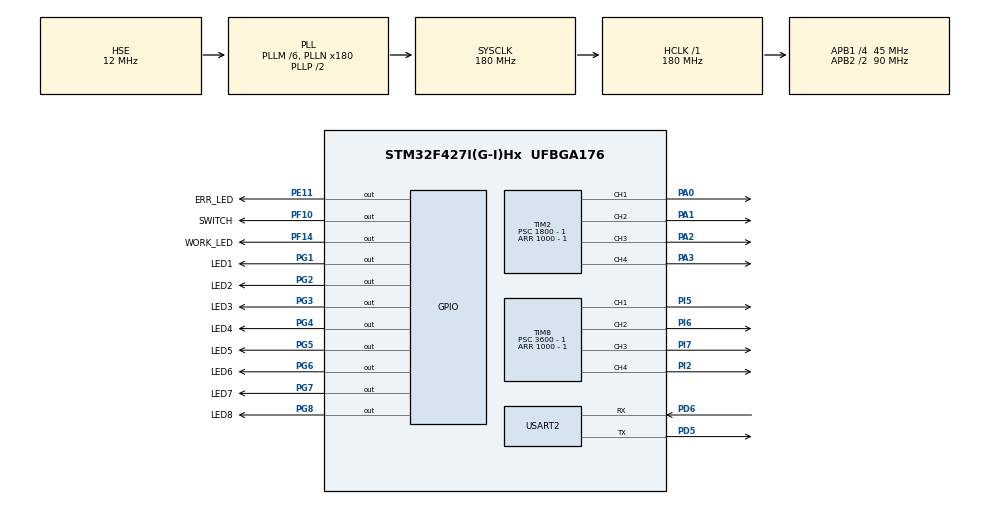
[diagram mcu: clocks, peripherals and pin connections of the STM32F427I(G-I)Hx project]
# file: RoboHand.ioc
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FREERTOS.Tasks01=root_task,24,640,root_task_handler,As weak,NULL,Dynamic,NULL,NULL
FREERTOS.configCHECK_FOR_STACK_OVERFLOW=2
FREERTOS.configENABLE_FPU=1
FREERTOS.configMINIMAL_STACK_SIZE=256
FREERTOS.configRECORD_STACK_HIGH_ADDRESS=1
FREERTOS.configTOTAL_HEAP_SIZE=51200
Mcu.Family=STM32F4
Mcu.Name=STM32F427I(G-I)Hx
Mcu.Package=UFBGA176
NVIC.PriorityGroup=NVIC_PRIORITYGROUP_4
NVIC.TIM1_BRK_TIM9_IRQn=true\:15\:0\:false\:false\:true\:false\:false\:true\:true
NVIC.TIM4_IRQn=true\:5\:0\:false\:false\:true\:true\:true\:true\:true
NVIC.TimeBase=TIM1_BRK_TIM9_IRQn
NVIC.TimeBaseIP=TIM9
NVIC.USART2_IRQn=true\:5\:0\:false\:false\:true\:true\:true\:true\:true
PA0/WKUP.Signal=S_TIM2_CH1_ETR
PA1.Signal=S_TIM2_CH2
PA13.Mode=Serial_Wire
PA13.Signal=SYS_JTMS-SWDIO
PA14.Mode=Serial_Wire
PA14.Signal=SYS_JTCK-SWCLK
PA2.Signal=S_TIM2_CH3
PA3.Signal=S_TIM2_CH4
PD5.Mode=Asynchronous
PD5.Signal=USART2_TX
PD6.Mode=Asynchronous
PD6.Signal=USART2_RX
PE11.GPIO_Label=ERR_LED
PE11.PinState=GPIO_PIN_SET
PE11.Signal=GPIO_Output
PF10.GPIO_Label=SWITCH
PF10.GPIO_ModeDefaultOutputPP=GPIO_MODE_OUTPUT_PP
PF10.GPIO_PuPd=GPIO_PULLDOWN
PF10.PinState=GPIO_PIN_RESET
PF10.Signal=GPIO_Output
PF14.GPIO_Label=WORK_LED
PF14.PinState=GPIO_PIN_SET
PF14.Signal=GPIO_Output
PG1.GPIO_Label=LED1
PG1.PinState=GPIO_PIN_SET
PG1.Signal=GPIO_Output
PG2.GPIO_Label=LED2
PG2.PinState=GPIO_PIN_SET
PG2.Signal=GPIO_Output
PG3.GPIO_Label=LED3
PG3.PinState=GPIO_PIN_SET
PG3.Signal=GPIO_Output
PG4.GPIO_Label=LED4
PG4.PinState=GPIO_PIN_SET
PG4.Signal=GPIO_Output
PG5.GPIO_Label=LED5
PG5.PinState=GPIO_PIN_SET
PG5.Signal=GPIO_Output
PG6.GPIO_Label=LED6
PG6.PinState=GPIO_PIN_SET
PG6.Signal=GPIO_Output
PG7.GPIO_Label=LED7
PG7.PinState=GPIO_PIN_SET
PG7.Signal=GPIO_Output
PG8.GPIO_Label=LED8
PG8.PinState=GPIO_PIN_SET
PG8.Signal=GPIO_Output
PH0/OSC_IN.Mode=HSE-External-Oscillator
PH0/OSC_IN.Signal=RCC_OSC_IN
PH1/OSC_OUT.Mode=HSE-External-Oscillator
PH1/OSC_OUT.Signal=RCC_OSC_OUT
PI2.Signal=S_TIM8_CH4
PI5.Signal=S_TIM8_CH1
PI6.Signal=S_TIM8_CH2
PI7.Signal=S_TIM8_CH3
ProjectManager.HeapSize=0x200
ProjectManager.StackSize=0x400
ProjectManager.TargetToolchain=CMake
RCC.48MHZClocksFreq_Value=90000000
RCC.AHBFreq_Value=180000000
RCC.APB1CLKDivider=RCC_HCLK_DIV4
RCC.APB1Freq_Value=45000000
RCC.APB1TimFreq_Value=90000000
RCC.APB2CLKDivider=RCC_HCLK_DIV2
RCC.APB2Freq_Value=90000000
RCC.APB2TimFreq_Value=180000000
RCC.CortexFreq_Value=180000000
RCC.HCLKFreq_Value=180000000
RCC.HSE_VALUE=12000000
RCC.HSI_VALUE=16000000
RCC.LSE_VALUE=32768
RCC.PLLM=6
RCC.PLLN=180
RCC.PLLSourceVirtual=RCC_PLLSOURCE_HSE
RCC.SYSCLKFreq_VALUE=180000000
RCC.SYSCLKSource=RCC_SYSCLKSOURCE_PLLCLK
RCC.VCOOutputFreq_Value=360000000
SH.S_TIM2_CH1_ETR.0=TIM2_CH1,PWM Generation1 CH1
SH.S_TIM2_CH2.0=TIM2_CH2,PWM Generation2 CH2
SH.S_TIM2_CH3.0=TIM2_CH3,PWM Generation3 CH3
SH.S_TIM2_CH4.0=TIM2_CH4,PWM Generation4 CH4
SH.S_TIM8_CH1.0=TIM8_CH1,PWM Generation1 CH1
SH.S_TIM8_CH2.0=TIM8_CH2,PWM Generation2 CH2
SH.S_TIM8_CH3.0=TIM8_CH3,PWM Generation3 CH3
SH.S_TIM8_CH4.0=TIM8_CH4,PWM Generation4 CH4
TIM2.AutoReloadPreload=TIM_AUTORELOAD_PRELOAD_ENABLE
TIM2.Channel-PWM\ Generation1\ CH1=TIM_CHANNEL_1
TIM2.Channel-PWM\ Generation2\ CH2=TIM_CHANNEL_2
TIM2.Channel-PWM\ Generation3\ CH3=TIM_CHANNEL_3
TIM2.Channel-PWM\ Generation4\ CH4=TIM_CHANNEL_4
TIM2.Period=1000 - 1
TIM2.Prescaler=1800 - 1
TIM4.AutoReloadPreload=TIM_AUTORELOAD_PRELOAD_ENABLE
TIM4.Period=1000 - 1
TIM4.Prescaler=90 - 1
TIM8.AutoReloadPreload=TIM_AUTORELOAD_PRELOAD_ENABLE
TIM8.Channel-PWM\ Generation1\ CH1=TIM_CHANNEL_1
TIM8.Channel-PWM\ Generation2\ CH2=TIM_CHANNEL_2
TIM8.Channel-PWM\ Generation3\ CH3=TIM_CHANNEL_3
TIM8.Channel-PWM\ Generation4\ CH4=TIM_CHANNEL_4
TIM8.Period=1000 - 1
TIM8.Prescaler=3600 - 1
USART2.VirtualMode=VM_ASYNC
VP_FREERTOS_VS_CMSIS_V2.Mode=CMSIS_V2
VP_SYS_VS_tim9.Mode=TIM9
VP_TIM2_VS_ClockSourceINT.Mode=Internal
VP_TIM4_VS_ClockSourceINT.Mode=Internal
VP_TIM8_VS_ClockSourceINT.Mode=Internal
board=custom

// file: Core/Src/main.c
/* USER CODE BEGIN Header */
/**
 ******************************************************************************
 * @file           : main.c
 * @brief          : Main program body
 ******************************************************************************
 * @attention
 *
 * Copyright (c) 2024 STMicroelectronics.
 * All rights reserved.
 *
 * This software is licensed under terms that can be found in the LICENSE file
 * in the root directory of this software component.
 * If no LICENSE file comes with this software, it is provided AS-IS.
 *
 ******************************************************************************
 */
/* USER CODE END Header */
#include "main.h"
#include "cmsis_os.h"
#include "tim.h"
#include "usart.h"
#include "gpio.h"

void SystemClock_Config(void);
void MX_FREERTOS_Init(void);

int main(void)
{

  /* MCU Configuration--------------------------------------------------------*/

  /* Reset of all peripherals, Initializes the Flash interface and the Systick. */
  HAL_Init();

  /* Configure the system clock */
  SystemClock_Config();

  /* Initialize all configured peripherals */
  MX_GPIO_Init();
  MX_TIM2_Init();
  MX_TIM8_Init();
  MX_USART2_UART_Init();
  MX_TIM4_Init();

  /* Init scheduler */
  osKernelInitialize();

  /* Call init function for freertos objects (in cmsis_os2.c) */
  MX_FREERTOS_Init();

  /* Start scheduler */
  osKernelStart();

  /* We should never get here as control is now taken by the scheduler */

  /* Infinite loop */
    while (1)
    {

    }
}

void SystemClock_Config(void)
{
  RCC_OscInitTypeDef RCC_OscInitStruct = {0};
  RCC_ClkInitTypeDef RCC_ClkInitStruct = {0};

  /** Configure the main internal regulator output voltage
  */
  __HAL_RCC_PWR_CLK_ENABLE();
  __HAL_PWR_VOLTAGESCALING_CONFIG(PWR_REGULATOR_VOLTAGE_SCALE1);

  /** Initializes the RCC Oscillators according to the specified parameters
  * in the RCC_OscInitTypeDef structure.
  */
  RCC_OscInitStruct.OscillatorType = RCC_OSCILLATORTYPE_HSE;
  RCC_OscInitStruct.HSEState = RCC_HSE_ON;
  RCC_OscInitStruct.PLL.PLLState = RCC_PLL_ON;
  RCC_OscInitStruct.PLL.PLLSource = RCC_PLLSOURCE_HSE;
  RCC_OscInitStruct.PLL.PLLM = 6;
  RCC_OscInitStruct.PLL.PLLN = 180;
  RCC_OscInitStruct.PLL.PLLP = RCC_PLLP_DIV2;
  RCC_OscInitStruct.PLL.PLLQ = 4;
  if (HAL_RCC_OscConfig(&RCC_OscInitStruct) != HAL_OK)
  {
    Error_Handler();
  }

  /** Activate the Over-Drive mode
  */
  if (HAL_PWREx_EnableOverDrive() != HAL_OK)
  {
    Error_Handler();
  }

  /** Initializes the CPU, AHB and APB buses clocks
  */
  RCC_ClkInitStruct.ClockType = RCC_CLOCKTYPE_HCLK|RCC_CLOCKTYPE_SYSCLK
                              |RCC_CLOCKTYPE_PCLK1|RCC_CLOCKTYPE_PCLK2;
  RCC_ClkInitStruct.SYSCLKSource = RCC_SYSCLKSOURCE_PLLCLK;
  RCC_ClkInitStruct.AHBCLKDivider = RCC_SYSCLK_DIV1;
  RCC_ClkInitStruct.APB1CLKDivider = RCC_HCLK_DIV4;
  RCC_ClkInitStruct.APB2CLKDivider = RCC_HCLK_DIV2;

  if (HAL_RCC_ClockConfig(&RCC_ClkInitStruct, FLASH_LATENCY_5) != HAL_OK)
  {
    Error_Handler();
  }
}

/* USER CODE BEGIN 4 */

__weak void Robo_App_Timer_Update(void)
{
}

/* USER CODE END 4 */

void HAL_TIM_PeriodElapsedCallback(TIM_HandleTypeDef *htim)
{
  if (htim->Instance == TIM9) {
    HAL_IncTick();
  }
  /* USER CODE BEGIN Callback 1 */
    if (htim == &htim4)
    {
        Robo_App_Timer_Update();
    }

  /* USER CODE END Callback 1 */
}

void Error_Handler(void)
{
    __disable_irq();
    while (1)
    {
    }
}

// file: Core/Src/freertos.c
/* USER CODE BEGIN Header */
/**
 ******************************************************************************
 * File Name          : freertos.c
 * Description        : Code for freertos applications
 ******************************************************************************
 * @attention
 *
 * Copyright (c) 2024 STMicroelectronics.
 * All rights reserved.
 *
 * This software is licensed under terms that can be found in the LICENSE file
 * in the root directory of this software component.
 * If no LICENSE file comes with this software, it is provided AS-IS.
 *
 ******************************************************************************
 */
/* USER CODE END Header */

#include "FreeRTOS.h"
#include "task.h"
#include "main.h"
#include "cmsis_os.h"

/* Definitions for root_task */
osThreadId_t root_taskHandle;
const osThreadAttr_t root_task_attributes = {
  .name = "root_task",
  .stack_size = 640 * 4,
  .priority = (osPriority_t) osPriorityNormal,
};

void root_task_handler(void *argument);

void MX_FREERTOS_Init(void); /* (MISRA C 2004 rule 8.1) */

/* Hook prototypes */
void vApplicationStackOverflowHook(xTaskHandle xTask, signed char *pcTaskName);

/* USER CODE BEGIN 4 */
void vApplicationStackOverflowHook(xTaskHandle xTask, signed char *pcTaskName)
{
    /* Run time stack overflow checking is performed if
    configCHECK_FOR_STACK_OVERFLOW is defined to 1 or 2. This hook function is
    called if a stack overflow is detected. */
}
/* USER CODE END 4 */

void MX_FREERTOS_Init(void) {

  /* Create the thread(s) */
  /* creation of root_task */
  root_taskHandle = osThreadNew(root_task_handler, NULL, &root_task_attributes);

}

__weak void root_task_handler(void *argument)
{
    for (;;)
    {
        osDelay(1);
    }
}
